VERSION "fleet-can-dataset fcs2_profile_e v2.0 (SYNTHETIC, not OEM)"

NS_ :

BS_:

BU_: ABS BCM BMS CLU ECM EPS

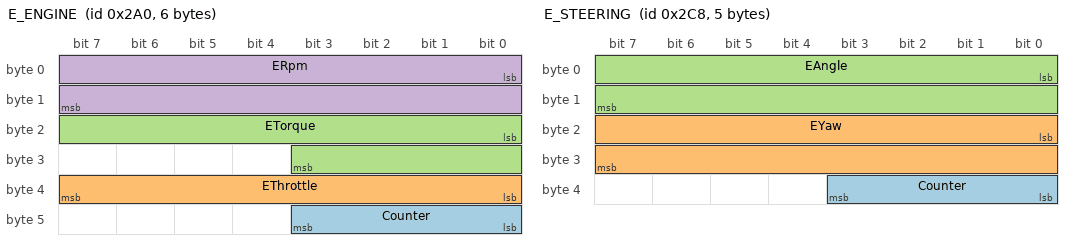
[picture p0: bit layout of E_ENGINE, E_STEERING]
BO_ 672 E_ENGINE: 6 ECM
 SG_ Counter : 40|4@1+ (1,0) [0|15] "" Vector__XXX
 SG_ EThrottle : 32|8@1+ (0.4,0) [0|102] "%" Vector__XXX
 SG_ ETorque : 16|12@1+ (0.5,0) [0|2047.5] "Nm" Vector__XXX
 SG_ ERpm : 0|16@1+ (0.25,0) [0|16383.75] "rpm" Vector__XXX

BO_ 712 E_STEERING: 5 EPS
 SG_ Counter : 32|4@1+ (1,0) [0|15] "" Vector__XXX
 SG_ EYaw : 16|16@1- (0.01,0) [-327.68|327.67] "deg/s" Vector__XXX
 SG_ EAngle : 0|16@1- (0.1,0) [-3276.8|3276.7] "deg" Vector__XXX

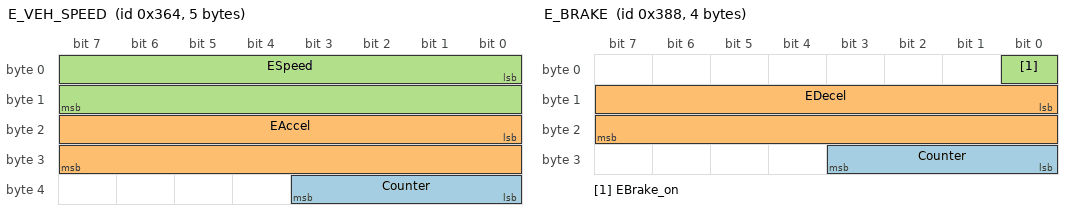
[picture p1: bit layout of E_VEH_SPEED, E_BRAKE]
BO_ 868 E_VEH_SPEED: 5 ABS
 SG_ Counter : 32|4@1+ (1,0) [0|15] "" Vector__XXX
 SG_ EAccel : 16|16@1- (0.001,0) [-32.768|32.767] "m/s^2" Vector__XXX
 SG_ ESpeed : 0|16@1+ (0.01,0) [0|655.35] "km/h" Vector__XXX

BO_ 904 E_BRAKE: 4 ABS
 SG_ Counter : 24|4@1+ (1,0) [0|15] "" Vector__XXX
 SG_ EDecel : 8|16@1+ (0.001,0) [0|65.535] "m/s^2" Vector__XXX
 SG_ EBrake_on : 0|1@1+ (1,0) [0|1] "" Vector__XXX

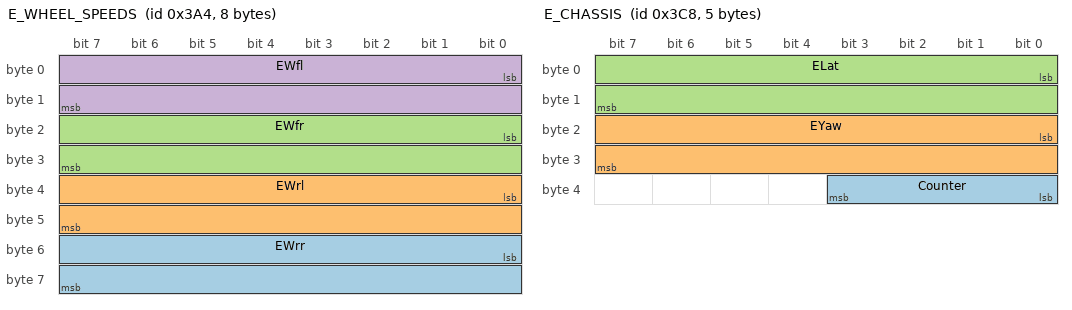
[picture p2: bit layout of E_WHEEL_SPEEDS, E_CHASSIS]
BO_ 932 E_WHEEL_SPEEDS: 8 ABS
 SG_ EWrr : 48|16@1+ (0.01,0) [0|655.35] "km/h" Vector__XXX
 SG_ EWrl : 32|16@1+ (0.01,0) [0|655.35] "km/h" Vector__XXX
 SG_ EWfr : 16|16@1+ (0.01,0) [0|655.35] "km/h" Vector__XXX
 SG_ EWfl : 0|16@1+ (0.01,0) [0|655.35] "km/h" Vector__XXX

BO_ 968 E_CHASSIS: 5 ABS
 SG_ Counter : 32|4@1+ (1,0) [0|15] "" Vector__XXX
 SG_ EYaw : 16|16@1- (0.01,0) [-327.68|327.67] "deg/s" Vector__XXX
 SG_ ELat : 0|16@1- (0.001,0) [-32.768|32.767] "m/s^2" Vector__XXX

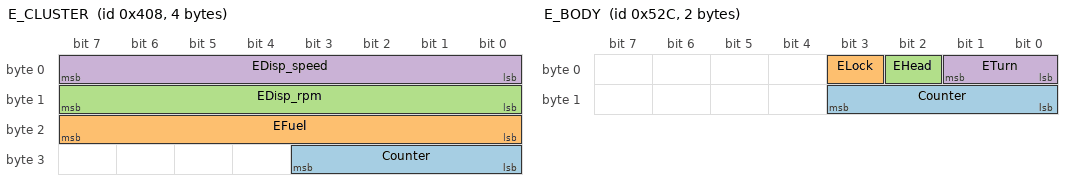
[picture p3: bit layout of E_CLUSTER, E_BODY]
BO_ 1032 E_CLUSTER: 4 CLU
 SG_ Counter : 24|4@1+ (1,0) [0|15] "" Vector__XXX
 SG_ EFuel : 16|8@1+ (0.4,0) [0|102] "%" Vector__XXX
 SG_ EDisp_rpm : 8|8@1+ (32,0) [0|8160] "rpm" Vector__XXX
 SG_ EDisp_speed : 0|8@1+ (1,0) [0|255] "km/h" Vector__XXX

BO_ 1156 E_BATTERY: 3 BMS
 SG_ Counter : 16|4@1+ (1,0) [0|15] "" Vector__XXX
 SG_ EBatt : 0|16@1+ (0.001,0) [0|65.535] "V" Vector__XXX

BO_ 1260 E_TURN_LAMP: 2 BCM
 SG_ Counter : 8|4@1+ (1,0) [0|15] "" Vector__XXX
 SG_ ETurn : 0|2@1+ (1,0) [0|3] "" Vector__XXX

BO_ 1324 E_BODY: 2 BCM
 SG_ Counter : 8|4@1+ (1,0) [0|15] "" Vector__XXX
 SG_ ELock : 3|1@1+ (1,0) [0|1] "" Vector__XXX
 SG_ EHead : 2|1@1+ (1,0) [0|1] "" Vector__XXX
 SG_ ETurn : 0|2@1+ (1,0) [0|3] "" Vector__XXX
